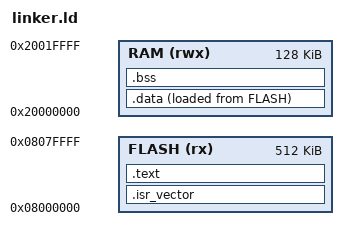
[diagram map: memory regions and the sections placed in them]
/* STM32F4xx linker script / STM32F4xx链接脚本 */
/* Memory layout for STM32F446RE */

MEMORY
{
    FLASH (rx)  : ORIGIN = 0x08000000, LENGTH = 512K
    RAM (rwx)   : ORIGIN = 0x20000000, LENGTH = 128K
}

ENTRY(Reset_Handler)

SECTIONS
{
    .isr_vector : {
        . = ALIGN(4);
        KEEP(*(.isr_vector))
        . = ALIGN(4);
    } > FLASH

    .text : {
        . = ALIGN(4);
        *(.text)
        *(.text*)
        *(.rodata)
        *(.rodata*)
        . = ALIGN(4);
        _etext = .;
    } > FLASH

    .data : {
        . = ALIGN(4);
        _sdata = .;
        *(.data)
        *(.data*)
        . = ALIGN(4);
        _edata = .;
    } > RAM AT > FLASH

    .bss : {
        . = ALIGN(4);
        _sbss = .;
        *(.bss)
        *(.bss*)
        *(COMMON)
        . = ALIGN(4);
        _ebss = .;
    } > RAM

    _estack = ORIGIN(RAM) + LENGTH(RAM);
}
